VERSION ""

NS_ :

BS_:

BU_: VCU OBC

BO_ 3221225472 VECTOR__INDEPENDENT_SIG_MSG: 0 Vector__XXX
 SG_ OBCMsg7Sig6 : 0|8@0+ (1,0) [0|1] "" Vector__XXX
 SG_ OBCMsg7Sig7 : 0|8@0+ (1,0) [0|1] "" Vector__XXX

BO_ 668 VcuChargerMsg14: 8 VCU

BO_ 802 VcuChargerMsg13: 8 VCU

BO_ 923 VcuChargerMsg12: 8 VCU

BO_ 918 VcuChargerMsg10: 8 VCU

BO_ 922 VcuChargerMsg11: 8 VCU

BO_ 916 VcuChargerMsg9: 8 VCU

BO_ 835 VcuChargerMsg7: 8 VCU

BO_ 814 VcuChargerMsg6: 8 VCU

BO_ 667 VcuChargerMsg5: 8 VCU

BO_ 831 VcuChargerMsg4: 8 VCU

BO_ 497 VcuChargerMsg3: 8 VCU

BO_ 663 VcuChargerMsg2: 8 VCU

BO_ 412 VcuChargerMsg1: 8 VCU

BO_ 1169 ChargerMsg9: 8 OBC

BO_ 951 ChargerMsg8: 8 OBC

BO_ 827 ChargerMsg7: 8 OBC

BO_ 1806 ChargerMsg4: 8 OBC

BO_ 932 ChargerMsg3: 8 OBC
 SG_ ChargerLvAmps2 : 23|8@0+ (0.125,0) [0|1] "A" Vector__XXX

BO_ 930 ChargerMsg2: 8 OBC
 SG_ ChargerHvVolts2 : 1|10@0+ (1,0) [0|1] "V" Vector__XXX

BO_ 927 ChargerMsg1: 8 OBC
 SG_ ChargerLvVolts : 15|8@0+ (0.125,0) [0|1] "V" Vector__XXX
 SG_ ChargerLvAmps : 39|8@0+ (0.125,0) [0|1] "A" Vector__XXX

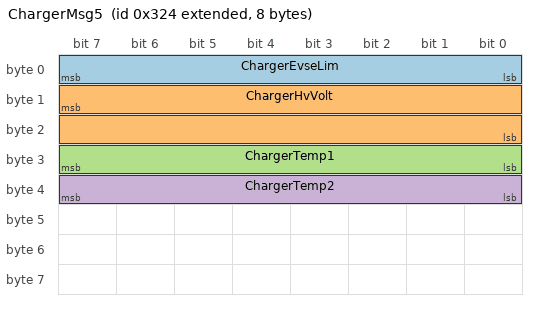
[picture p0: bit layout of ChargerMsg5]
BO_ 2147484452 ChargerMsg5: 8 OBC
 SG_ ChargerEvseLim : 7|8@0+ (1,0) [0|255] "A" Vector__XXX
 SG_ ChargerHvVolt : 15|16@0- (0.02,0) [0|1] "V" Vector__XXX
 SG_ ChargerTemp1 : 31|8@0+ (1,0) [0|1] "" Vector__XXX
 SG_ ChargerTemp2 : 39|8@0+ (1,0) [0|1] "" Vector__XXX

BO_ 2147484451 ChargerMsg6: 8 OBC
 SG_ ChargerPlugState : 47|8@0+ (1,0) [0|1] "" Vector__XXX

BO_ 2147484477 ChargerMsg10: 8 OBC
 SG_ ChargerChargingBit : 61|1@0+ (1,0) [0|0] "" Vector__XXX
 SG_ ChargerHvCurCharging : 55|8@0+ (0.1,0) [0|25.5] "A" Vector__XXX
 SG_ OBCMsg7Sig1 : 7|8@0+ (1,0) [0|1] "" Vector__XXX
 SG_ OBCMsg7Sig3 : 23|8@0+ (1,0) [0|1] "" Vector__XXX
 SG_ OBCMsg7Sig2 : 15|8@0+ (1,0) [0|1] "" Vector__XXX
 SG_ OBCMsg7Sig4 : 31|8@0+ (1,0) [0|1] "" Vector__XXX
 SG_ OBCMsg7Sig5 : 39|8@0+ (1,0) [0|1] "" Vector__XXX
 SG_ OBCMsg7Sig8 : 63|8@0+ (1,0) [0|1] "" Vector__XXX

CM_ BO_ 3221225472 "This is a message for not used signals, created by Vector CANdb++ DBC OLE DB Provider.";
CM_ BO_ 916 "Impacts power level, not direct current and voltage
Byte 4 needs to be 0x10 to start";
CM_ BO_ 835 "always 0s";
CM_ BO_ 814 "Always 0s";
CM_ SG_ 932 ChargerLvAmps2 "Matches_LV_Amps";
CM_ SG_ 930 ChargerHvVolts2 "Matches_HV_reported";
BA_DEF_ BO_  "GenMsgBackgroundColor" STRING ;
BA_DEF_ BO_  "GenMsgForegroundColor" STRING ;
BA_DEF_ BO_  "filterlabeling" INT 0 0;
BA_DEF_DEF_  "GenMsgBackgroundColor" "#ffffff";
BA_DEF_DEF_  "GenMsgForegroundColor" "#000000";
BA_DEF_DEF_  "filterlabeling" 1;
BA_ "GenMsgForegroundColor" BO_ 2147484452 "#00aa00";
BA_ "GenMsgForegroundColor" BO_ 2147484451 "#00aa00";
